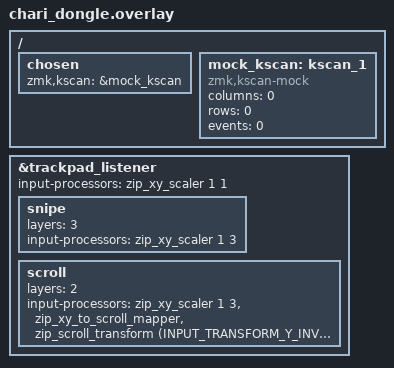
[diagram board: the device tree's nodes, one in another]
#include "chari.dtsi"
#include <dt-bindings/zmk/input_transform.h>
#include <input/processors.dtsi>

/ {
    chosen {
        zmk,kscan = &mock_kscan;
    };

    mock_kscan: kscan_1 {
        compatible = "zmk,kscan-mock";
        columns = <0>;
        rows = <0>;
        events = <0>;
    };
};

/* Enable the split listener — receives trackpad data from right peripheral */
&trackpad_listener {
    status = "okay";
    input-processors = <&zip_xy_scaler 1 1>;

    snipe {
        layers = <3>;
        input-processors = <&zip_xy_scaler 1 3>;
    };

    scroll {
        layers = <2>;
        input-processors = <&zip_xy_scaler 1 3>, <&zip_xy_to_scroll_mapper>, <&zip_scroll_transform (INPUT_TRANSFORM_Y_INVERT)>;
    };
};
